# PIC32CZ2051CA90208 register map
Vendor: Microchip Technology; Series: PIC32CZCA90; File version: 0
CPU: CM7 r1p1, little endian, MPU, FPU, double-precision FPU, I-cache, D-cache, ITCM, DTCM, 3 interrupt priority bits, 222 interrupts
Registers are 32-bit, read-write, reset 0x0 unless marked. A register's access mark holds for its fields unless they carry their own. Offsets are from the block's base; [hi:lo] are bit positions; {n}, {i} and the like mark numbered series; 'fields as' and 'values as' point back to an identical list.

## SPI_IXS0 — Audio SPI with 8 channels compatibilty
Base 0x46030000; register names take the prefix SPI_IXS_
Same registers: SPI_IXS1 0x45030000
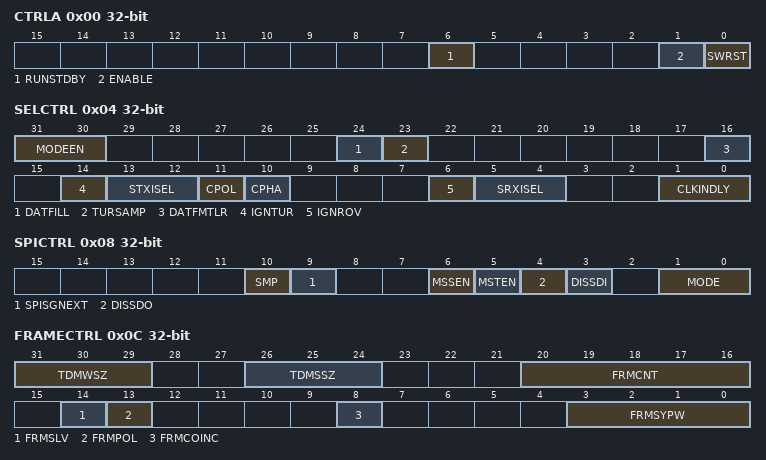
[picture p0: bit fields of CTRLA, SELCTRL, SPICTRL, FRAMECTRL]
0x00 CTRLA — SPI Control Enable Register
  [6] RUNSTDBY — RUN STANDBY Mode Enable bit
  [1] ENABLE — SPI Enable (ON) bit
  [0] SWRST — SPI Software Reset
0x04 SELCTRL — SPI Control Options Select Register
  [31:30] MODEEN — MACRO MODE ENABLED
    0=DFTLEN (Default Mode); 1=AUDEN (Audio Mode); 2=TDMEN (Framed Mode); 3=TPDEN (Broadcast Mode)
  [24] DATFILL — DATFILL undefined bits 1 or 0
  [23] TURSAMP — Transmit Under-run last sample sent
  [16] DATFMTLR — Packed data format -- left or right justified
  [14] IGNTUR — Ignore Transmit Underrun (for Audio Data Transmissions)
  [13:12] STXISEL — SPI Transmit Service Request Interrupt Select
    0=TXBSREMPTY (TXB And SR Empty); 1=TXBEMPTY; 2=TXBHEMPTY (TXB Half Empty); 3=TXBNFULL (TXB Not Full)
  [11] CPOL — Clock Polarity Select bit
  [10] CPHA — SPI Clock Edge Select bit
  [6] IGNROV — Ignore Receive Overflow (for Audio Data Transmissions)
  [5:4] SRXISEL — SPI Receive Service Request Interrupt Select
    0=RXBEMPTY; 1=RXBNEMPTY (RXB Not Empty); 2=RXBHFULL (RXB Half Full); 3=RXBFULL
  [1:0] CLKINDLY — Serial Clock Input Delay for SDI sampling
    0=TDLY0 (0 Tap Delays); 1=TDLY1 (1 Tap Delay); 2=TDLY2 (2 Tap Delay); 3=TDLY3 (3 Tap Delay)
0x08 SPICTRL — SPI Control Register
  [10] SMP — SPI Data Input Sample Phase bit
  [9] SPISGNEXT — Sign Extend Read Data from the RX FIFO
  [6] MSSEN — Master/Slave Mode Select Enable bit
  [5] MSTEN — Master Mode Enable bit
  [4] DISSDO — Disable SDO bit
  [3] DISSDI — Disable SDI bit
  [1:0] MODE — Serial Word Length bits for AUDEN=0, not used when AUDEN=1
    0=8 Bits Mode; 1=16 Bits Mode; 2=32 Bits Mode
0x0C FRAMECTRL — SPI Control Frame Register
  [31:29] TDMWSZ — TDM Number of Bits in a Word Size
    0=WDSZ8 (Word Size 8); 1=WDSZ12 (Word Size 12); 2=WDSZ16 (Word Size 16); 3=WDSZ20 (Word Size 20); 4=WDSZ24 (Word Size 24); 5=WDSZ28 (Word Size 28); 6=WDSZ32 (Word Size 32)
  [26:24] TDMSSZ — TDM Number of Bits in a Slot Size
    0=SLTSZ8 (Slot Size 8); 1=SLTSZ12 (Slot Size 12); 2=SLTSZ16 (Slot Size 16); 3=SLTSZ20 (Slot Size 20); 4=SLTSZ24 (Slot Size 24); 5=SLTSZ28 (Slot Size 28); 6=SLTSZ32 (Slot Size 32)
  [20:16] FRMCNT — Frame sync pulse counter
    0=CNT1 (Generate a Frame sync pulse on each serial word); {v}=CNT{v+1} (Number of slots per frame sync pulse is {v+1}) (v=1..5); 6=CNT8 (Number of slots per frame sync pulse is 8); 7=CNT10 (Number of slots per frame sync pulse is 10); 8=CNT12 (Number of slots per frame sync pulse is 12); 9=CNT14 (Number of slots per frame sync pulse is 14); 10=CNT16 (Number of slots per frame sync pulse is 16); 11=CNT18 (Number of slots per frame sync pulse is 18); 12=CNT20 (Number of slots per frame sync pulse is 20); 13=CNT22 (Number of slots per frame sync pulse is 22); 14=CNT24 (Number of slots per frame sync pulse is 24); 15=CNT26 (Number of slots per frame sync pulse is 26); 16=CNT28 (Number of slots per frame sync pulse is 28); 17=CNT30 (Number of slots per frame sync pulse is 30); 18=CNT32 (Number of slots per frame sync pulse is 32)
  [14] FRMSLV — Frame Sync Pulse Direction Control bit
  [13] FRMPOL — Frame Sync / Slave Select Polarity bit
  [8] FRMCOINC — Frame Sync Pulse Edge Select bit
  [3:0] FRMSYPW — Frame sync pulse width in serial words
    0=SYPW0 (Frame sync pulse is one clock wide); 1=SYPW1 (Frame sync pulse is one slots wide); 2=SYPW2 (Frame sync pulse is two slots wide); 3=SYPW3 (Frame sync pulse is three slots wide); 4=SYPW4 (Frame sync pulse is four slots wide); 5=SYPW5 (Frame sync pulse is five slots wide); 6=SYPW6 (Frame sync pulse is six slots wide); 7=SYPW7 (Frame sync pulse is seven slots wide); 8=SYPW8 (Frame sync pulse is eight slots wide); 9=SYPW16 (Frame sync pulse is sixteen slots wide); 10=SYPW31 (Frame sync pulse is thirty one slots wide)
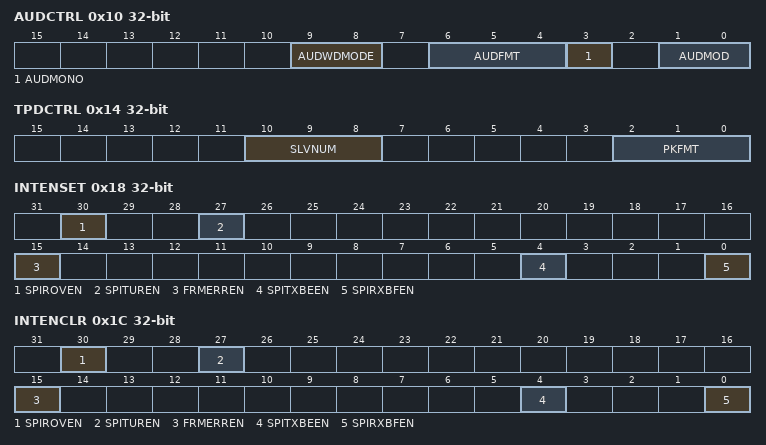
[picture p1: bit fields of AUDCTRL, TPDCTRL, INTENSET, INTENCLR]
0x10 AUDCTRL — SPI Control Audio Register
  [9:8] AUDWDMODE — Serial Word Length bits (Ignored when AUDEN=0)
  [6:4] AUDFMT — Audio Protocol Format
    0=I2SLEGACY (Legacy I2S Mode); 1=I2SRAW (I2S Raw Audio Format); 2=I2SOTHER824 (I2S Other AM824 Format); 4=I8SOTHER (I8S Other Format); 5=I8SRAW (I8S Raw Audio Format); 6=I8SOTHER824 (I8S Other AM824 Format)
  [3] AUDMONO — Transmit audio data format
  [1:0] AUDMOD — Audio Protocol Mode
    0=STDMODE (I2S/I8S Standard Mode); 1=LJRJMODE (I2S/I8S Left Or Right Justified); 3=PCMMODE (PCM/DSP Mode)
0x14 TPDCTRL — SPI Control Tpd Register
  [10:8] SLVNUM — Number of the Slave designated: to be used with the PKFMT to determine the slave.
    {v}=SLAVE{v} (v=0..4)
  [2:0] PKFMT — Master Slave TPD mode.
    0=PKT4x32 (32 bit data in 4x32 packed format); 1=PKT3x32 (32 bit data in 3x32 packed format); 2=PKT4x24 (24 bit data in 4x24 packed format); 3=PKT3x24 (24 bit data in 3x24 packed format); 4=PKT6x16 (16 bit data in 6x16 packed format); 5=PKT4x16 (16 bit data in 4x16 packed format); 6=PKT2x16 (16 bit data in 2x16 packed format)
0x18 INTENSET write-1-sets — SPI Interrupt Enable Set Register
  [30] SPIROVEN — Enable Interrupt Events via SPIROV
  [27] SPITUREN — Enable Interrupt Events via SPITUR
  [15] FRMERREN — Enable Interrupt Events via FRMERR
  [4] SPITXBEEN — Enablie Interrupt Events via SPITXBE
  [0] SPIRXBFEN — Enablie Interrupt Events via SPIRXBF
0x1C INTENCLR write-1-clears — SPI Interrupt Enable Clear Register
  fields as INTENSET
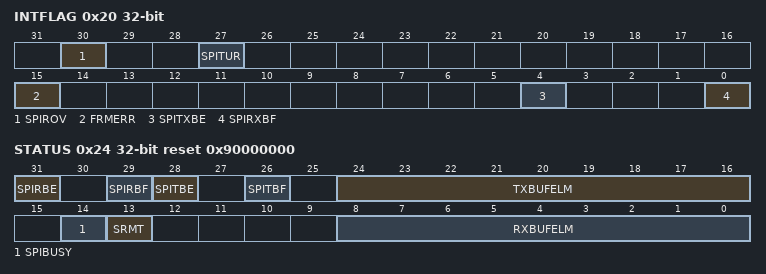
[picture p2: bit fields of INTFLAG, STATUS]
0x20 INTFLAG write-1-clears — SPI Interrupt Flag Register
  [30] SPIROV — Receive Overflow Status bit
  [27] SPITUR — Transmit Underrun Status bit
  [15] FRMERR — SPI Frame Error Status bit
  [4] SPITXBE — SPI Transmit Buffer Empty Status Bit
  [0] SPIRXBF — SPI Receive Buffer Full Status Bit
0x24 STATUS ro reset 0x90000000 — SPI Status Register
  [31] SPIRBE — RX Buffer Empty bit
  [29] SPIRBF — SPI Receive Buffer Full status bit
  [28] SPITBE — SPI Transmit Buffer Empty status bit
  [26] SPITBF — SPI Transmit Buffer Full Status bit
  [24:16] TXBUFELM — Transmit Buffer Element Count bits
  [14] SPIBUSY — SPI activity status bit
  [13] SRMT — Register (SR) Empty bit
  [8:0] RXBUFELM — Receive Buffer Element Count bits
0x28 BUF — SPI Buffer Register
  [31:0] DATA — FIFO Data bits
0x2C BRG — SPI Baud Rate Register
  [12:0] BRG — Baud Rate Divisor bits
0x30 DBGCTRL — SPI Debug Control Register
  [0] DBGRUN — Debug Running State
0x34 SYNCBUSY ro — SPI Sync Busy Register
  [0] SWRSTBSY — Software reset busy bit --- Synchronizing Busy bit for swrst
0x38 EVCTRL — SPI Event Control Register
  [0] FPSEEN — Frame Pulse Event Enable Bit

## Notices in the file
Copyright (c) 2026 Microchip Technology Inc.
SPDX-License-Identifier: Apache-2.0
Licensed under the Apache License, Version 2.0 (the "License");
you may not use this file except in compliance with the License.
You may obtain a copy of the License at
http://www.apache.org/licenses/LICENSE-2.0
Unless required by applicable law or agreed to in writing, software
distributed under the License is distributed on an "AS IS" BASIS,
WITHOUT WARRANTIES OR CONDITIONS OF ANY KIND, either express or implied.
See the License for the specific language governing permissions and
limitations under the License.
